# MKV56F22 register map
Vendor: Freescale Semiconductor, Inc.; Series: Kinetis_V; File version: 1.6
CPU: CM7 r0p1, little endian, no MPU, FPU, VTOR, 4 interrupt priority bits
Registers are 32-bit, read-write, reset 0x0 unless marked. A register's access mark holds for its fields unless they carry their own. Offsets are from the block's base; [hi:lo] are bit positions; {n}, {i} and the like mark numbered series; 'fields as' and 'values as' point back to an identical list.

## EWM — External Watchdog Monitor
Base 0x40061000; register names take the prefix EWM_
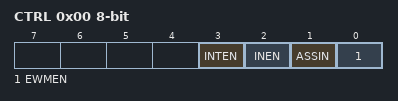
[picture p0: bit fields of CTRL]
0x00 CTRL 8-bit — Control Register
  [3] INTEN — Interrupt Enable.
  [2] INEN — Input Enable.
  [1] ASSIN — EWM_in's Assertion State Select.
  [0] EWMEN — EWM enable.
0x01 SERV 8-bit wo — Service Register
  [7:0] SERVICE — The EWM service mechanism requires the CPU to write two values to the SERV register: a first data byte of 0xB4, followed by a second data byte of 0x2C
0x02 CMPL 8-bit — Compare Low Register
  [7:0] COMPAREL — To prevent runaway code from changing this field, software should write to this field after a CPU reset even if the (default) minimum service time is required
0x03 CMPH 8-bit reset 0xFF — Compare High Register
  [7:0] COMPAREH — To prevent runaway code from changing this field, software should write to this field after a CPU reset even if the (default) maximum service time is required
0x04 CLKCTRL 8-bit — Clock Control Register
  [1:0] CLKSEL — EWM has 4 possible low power clock sources for running EWM counter
0x05 CLKPRESCALER 8-bit — Clock Prescaler Register
  [7:0] CLK_DIV — Selected low power clock source for running the EWM counter can be prescaled as below

## OSC0 — Oscillator
Base 0x40065000; register names take the prefix OSC0_
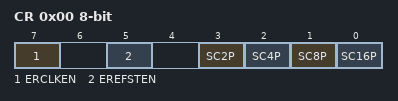
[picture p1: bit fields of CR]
0x00 CR 8-bit — OSC Control Register
  [7] ERCLKEN — External Reference Enable
    0=External reference clock is inactive; 1=External reference clock is enabled
  [5] EREFSTEN — External Reference Stop Enable
    0=External reference clock is disabled in Stop mode; 1=External reference clock stays enabled in Stop mode if ERCLKEN is set before entering Stop mode
  [3] SC2P — Oscillator 2 pF Capacitor Load Configure
    0=Disable the selection; 1=Add 2 pF capacitor to the oscillator load
  [2] SC4P — Oscillator 4 pF Capacitor Load Configure
    0=Disable the selection; 1=Add 4 pF capacitor to the oscillator load
  [1] SC8P — Oscillator 8 pF Capacitor Load Configure
    0=Disable the selection; 1=Add 8 pF capacitor to the oscillator load
  [0] SC16P — Oscillator 16 pF Capacitor Load Configure
    0=Disable the selection; 1=Add 16 pF capacitor to the oscillator load
0x02 OSC_DIV 8-bit
  [7:6] ERPS — ERCLK prescaler
    0=The divisor ratio is 1; 1=The divisor ratio is 2; 2=The divisor ratio is 4; 3=The divisor ratio is 8

## LLWU — Low leakage wakeup unit
Base 0x4007C000; register names take the prefix LLWU_
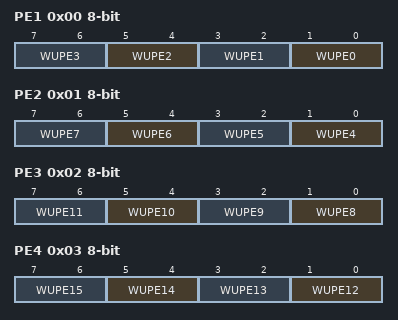
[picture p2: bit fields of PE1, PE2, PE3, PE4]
0x00 PE1 8-bit — LLWU Pin Enable 1 register
  [all] fields
    0=External input pin disabled as wakeup input; 1=External input pin enabled with rising edge detection; 2=External input pin enabled with falling edge detection; 3=External input pin enabled with any change detection
  [2n+1:2n] WUPE{n} (n=0..3) — Wakeup Pin Enable For LLWU_P{n}
0x01 PE2 8-bit — LLWU Pin Enable 2 register
  [all] fields
    values as the fields of PE1
  [2n-7:2n-8] WUPE{n} (n=4..7) — Wakeup Pin Enable For LLWU_P{n}
0x02 PE3 8-bit — LLWU Pin Enable 3 register
  [all] fields
    values as the fields of PE1
  [2n-15:2n-16] WUPE{n} (n=8..11) — Wakeup Pin Enable For LLWU_P{n}
0x03 PE4 8-bit — LLWU Pin Enable 4 register
  [all] fields
    values as the fields of PE1
  [2n-23:2n-24] WUPE{n} (n=12..15) — Wakeup Pin Enable For LLWU_P{n}
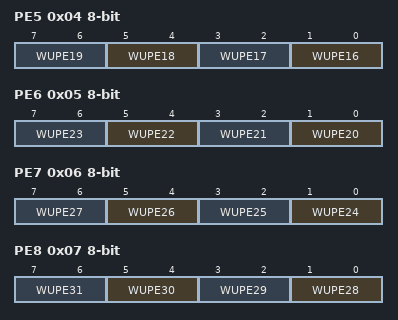
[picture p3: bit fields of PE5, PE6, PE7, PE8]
0x04 PE5 8-bit — LLWU Pin Enable 5 register
  [all] fields
    values as the fields of PE1
  [2n-31:2n-32] WUPE{n} (n=16..19) — Wakeup Pin Enable For LLWU_P{n}
0x05 PE6 8-bit — LLWU Pin Enable 6 register
  [all] fields
    values as the fields of PE1
  [2n-39:2n-40] WUPE{n} (n=20..23) — Wakeup Pin Enable For LLWU_P{n}
0x06 PE7 8-bit — LLWU Pin Enable 7 register
  [all] fields
    values as the fields of PE1
  [2n-47:2n-48] WUPE{n} (n=24..27) — Wakeup Pin Enable For LLWU_P{n}
0x07 PE8 8-bit — LLWU Pin Enable 8 register
  [all] fields
    values as the fields of PE1
  [2n-55:2n-56] WUPE{n} (n=28..31) — Wakeup Pin Enable For LLWU_P{n}
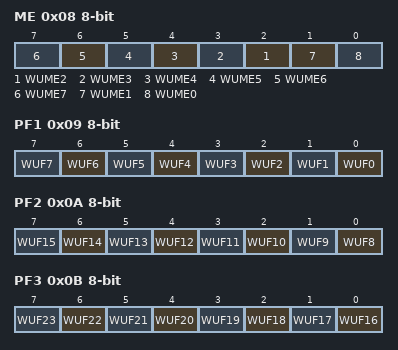
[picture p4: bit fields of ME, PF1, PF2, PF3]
0x08 ME 8-bit — LLWU Module Enable register
  [all] fields
    0=Internal module flag not used as wakeup source; 1=Internal module flag used as wakeup source
  [n] WUME{n} (n=2..7) — Wakeup Module Enable For Module {n}
  [1] WUME1 — Wakeup Module Enable for Module 1
  [0] WUME0 — Wakeup Module Enable For Module 0
0x09 PF1 8-bit — LLWU Pin Flag 1 register
  [n] WUF{n} (n=0..7) — Wakeup Flag For LLWU_P{n}
    0=LLWU_P{n} input was not a wakeup source; 1=LLWU_P{n} input was a wakeup source
0x0A PF2 8-bit — LLWU Pin Flag 2 register
  [n-8] WUF{n} (n=8..15) — Wakeup Flag For LLWU_P{n}
    values as PF1.WUF0
0x0B PF3 8-bit — LLWU Pin Flag 3 register
  [n-16] WUF{n} (n=16..23) — Wakeup Flag For LLWU_P{n}
    values as PF1.WUF0
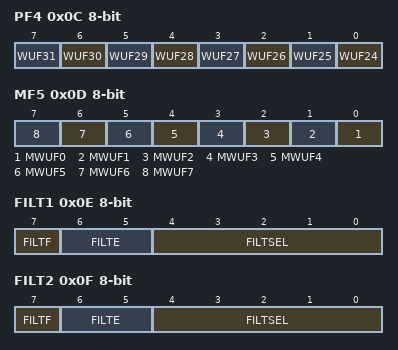
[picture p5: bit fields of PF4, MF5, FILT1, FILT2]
0x0C PF4 8-bit — LLWU Pin Flag 4 register
  [n-24] WUF{n} (n=24..31) — Wakeup Flag For LLWU_P{n}
    values as PF1.WUF0
0x0D MF5 8-bit ro — LLWU Module Flag 5 register
  [n] MWUF{n} (n=0..7) — Wakeup flag For module {n}
    0=Module {n} input was not a wakeup source; 1=Module {n} input was a wakeup source
0x0E FILT1 8-bit — LLWU Pin Filter 1 register
  [7] FILTF — Filter Detect Flag
    0=Pin Filter 1 was not a wakeup source; 1=Pin Filter 1 was a wakeup source
  [6:5] FILTE — Digital Filter On External Pin
    0=Filter disabled; 1=Filter posedge detect enabled; 2=Filter negedge detect enabled; 3=Filter any edge detect enabled
  [4:0] FILTSEL — Filter Pin Select
    0=Select LLWU_P0 for filter; 31=Select LLWU_P31 for filter
0x0F FILT2 8-bit — LLWU Pin Filter 2 register
  [7] FILTF — Filter Detect Flag
    0=Pin Filter 2 was not a wakeup source; 1=Pin Filter 2 was a wakeup source
  [6:5] FILTE — Digital Filter On External Pin
    values as FILT1.FILTE
  [4:0] FILTSEL — Filter Pin Select
    0=Select LLWU_P0 for filter; 31=Select LLWU_P31 for filter
